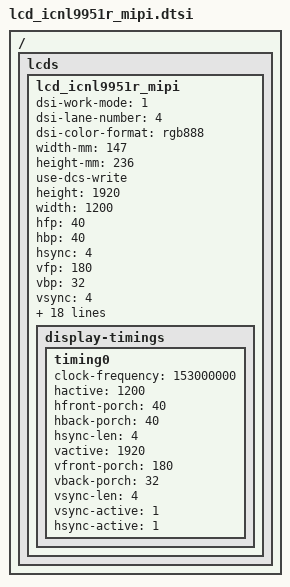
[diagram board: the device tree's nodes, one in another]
// SPDX-License-Identifier: GPL-2.0

/ { lcds: lcds {
	lcd_icnl9951r_mipi: lcd_icnl9951r_mipi {
		dsi-work-mode = <1>; /* video burst mode*/
		dsi-lane-number = <4>;
		dsi-color-format = "rgb888";
		width-mm = <147>;
		height-mm = <236>;
		use-dcs-write;

		/*mipi info*/
		height = <1920>;
		width = <1200>;
		hfp = <40>;
		hbp = <40>;
		hsync = <4>;
		vfp = <180>;
		vbp = <32>;
		vsync = <4>;
		fps = <60>;
		work-mode = <0>;
		rgb-mode = <3>;
		lane-number = <4>;
		phy-bit-clock = <1000000000>;
		phy-esc-clock = <76800000>;
		split-enable = <0>;
		eotp-enable = <0>;
		burst-mode = <2>;
		esd-check-enable = <0>;

		/* DSI_CMD, DSI_MODE, timeout, len, cmd */
		initial-command = [
			39 01 00 03 F0 5A 59
			39 01 00 03 F1 A5 A6
			39 01 00 21 B2 04 03 94 95 77 77 07 90 88 00 FF 00 FF 00 FF 00 FF 80 80 80 80 00 00 00 00 00 00 00 55 11 00 00
			39 01 00 21 B3 F2 01 02 09 8A A7 00 00 A7 00 00 11 34 01 01 01 01 00 00 00 00 00 00 00 03 06 80 80 01 00 00 00
			39 01 00 21 B4 0D 06 1A 1D 56 26 01 C7 33 33 AA 33 44 26 26 00 02 08 20 30 05 85 23 20 40 11 10 20 00 00 00 00
			39 01 00 21 B5 00 A8 A9 26 09 25 27 2D 2D 1B 19 17 15 13 11 0F 0D 05 23 03 03 03 03 03 C0 00 01 50 FF FF E0 00
			39 01 00 21 B6 00 A8 A9 26 08 24 27 2D 2D 1A 18 16 14 12 10 0E 0C 04 22 03 03 03 03 03 C0 00 01 50 FF FF E0 00
			39 01 00 21 B7 0F 03 C0 00 01 50 0F 03 C0 00 01 50 FF FF FF FF FD 50 55 55 55 55 55 50 03 03 C0 00 01 50 00 00
			39 01 00 21 B8 0F 03 C0 00 01 50 0F 03 C0 00 01 50 FF FF FF FF FD 50 55 55 55 55 55 50 03 03 C0 00 01 50 00 00
			39 01 00 21 B9 01 55 55 55 55 55 50 55 55 55 55 55 50 FF FF FF FF FD 50 FF FF FF FF FD 50 00 00 00 00 00 00 00
			39 01 00 10 BB 01 02 03 0A 04 13 14 12 16 5C 00 15 16 03 00
			39 01 00 21 BC FE F8 F0 00 00 00 00 04 00 05 80 02 24 00 B9 99 99 00 C4 09 C3 86 03 2E 11 00 00 00 00 00 00 00
			39 01 00 08 BD ED 23 42 52 52 1F 00
			39 01 00 21 BE 75 43 7E 43 0A 88 58 33 33 33 93 03 18 18 00 00 00 00 B2 AF B2 AF 00 00 00 00 00 00 00 00 00 00
			39 01 00 0B BF 0C 19 0C 19 00 11 22 04 58 00
			39 01 00 17 C0 40 90 17 41 23 56 F7 8A FF FF FF FF FF FF 3F FF 00 CC 02 00 01 B3
			39 01 00 21 C1 00 B4 00 1E 00 20 04 28 28 04 C7 80 05 32 C0 23 47 C0 10 FF 0F E7 00 00 00 00 00 00 00 00 00 00
			39 01 00 02 C2 00
			39 01 00 21 C3 00 FF 42 4D 01 00 00 00 00 00 00 00 00 97 10 10 2A 2A 2A 2A 2A 2A 2A 2A 40 00 00 00 00 00 00 00
			39 01 00 0F C4 0C 35 28 49 00 3F 00 50 00 1F 00 A3 F0 E7
			39 01 00 21 C5 03 13 10 57 5D 37 04 05 04 04 19 00 B4 2C 2B 2B BB AE 20 00 02 00 80 1D 15 06 13 64 FF 03 20 FF
			39 01 00 1E C7 76 54 32 22 34 56 77 77 20 76 54 32 22 34 56 77 77 20 42 00 21 FF FF 04 04 03 0E 07 00
			39 01 00 21 80 E8 D1 AE 8F 77 62 4E 3E 2F FE D9 B8 97 7B 62 33 01 D4 AA A7 7F 56 2B FD D2 9B 77 4A 3E 38 31 28
			39 01 00 21 81 E8 CE A8 89 72 5C 4A 39 2A FA D6 B5 95 79 60 31 FF D2 A9 A6 7E 56 2B FC D2 9B 77 4A 3E 38 32 28
			39 01 00 21 82 E8 CF AB 8C 74 5F 4C 3B 2C FC D7 B6 96 7A 61 32 00 D3 A9 A6 7E 56 2B FC D2 9B 77 4A 3E 38 31 28
			39 01 00 1A 83 09 1E 14 06 00 1E 14 06 00 1E 14 06 00 28 18 08 00 28 18 08 00 28 18 08 00
			39 01 00 1C 84 FF FF EA AA 95 54 00 00 00 FF FF EA AA 55 54 00 00 00 FF FF EA AA 95 54 00 00 00
			39 01 00 08 C8 42 00 48 EC E0 00 23
			39 01 00 07 D7 3F 04 0A 00 00 06
			39 01 00 05 D5 01 30 D4 10
			39 01 00 03 F1 5A 59
			39 01 00 03 F0 A5 A6
			39 01 00 02 35 00
			39 01 00 01 11
			39 01 00 01 29
			39 01 00 02 AC 05
		];
		sleep-in-command = [
			39 01 00 02 AC 0A
			39 01 00 01 28
			39 01 00 01 10
		];
		sleep-out-command = [
			39 01 00 01 11
			39 01 00 01 29
		];
		read-id-command = [
			37 01 00 01 01
			14 01 00 01 04
		];

		display-timings {
			timing0 {
				clock-frequency = <153000000>;
				hactive = <1200>;
				hfront-porch = <40>;
				hback-porch = <40>;
				hsync-len = <4>;
				vactive = <1920>;
				vfront-porch = <180>;
				vback-porch = <32>;
				vsync-len = <4>;
				vsync-active = <1>;
				hsync-active = <1>;
			};
		};
	};
};};
